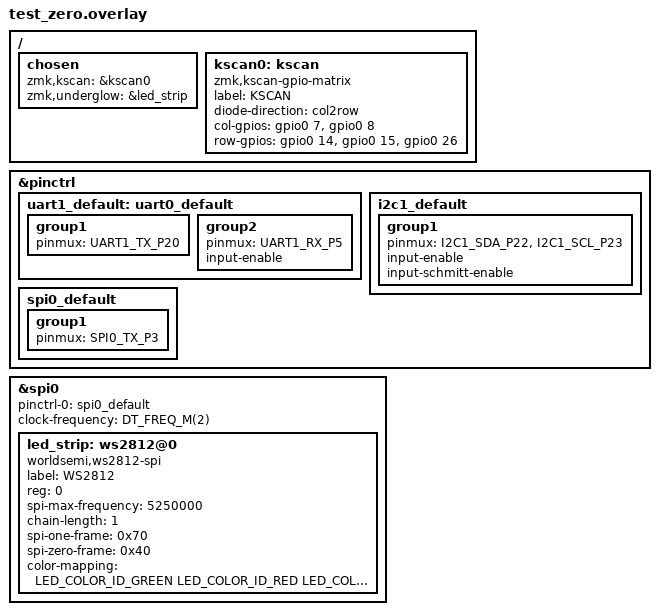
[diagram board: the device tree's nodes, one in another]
/*
 * Copyright (c) 2022 Gleb Sabirzyanov
 *
 * SPDX-License-Identifier: MIT
 */

#include <dt-bindings/zmk/matrix_transform.h>
#include <dt-bindings/led/led.h>


&pinctrl {
	uart1_default: uart0_default {
		group1 {
			pinmux = <UART1_TX_P20>;
		};
		group2 {
			pinmux = <UART1_RX_P5>;
			input-enable;
		};
	};

	i2c1_default: i2c1_default {
		group1 {
			pinmux = <I2C1_SDA_P22>, <I2C1_SCL_P23>;
			input-enable;
			input-schmitt-enable;
		};
	};


	spi0_default: spi0_default {
		group1 {
			pinmux = <SPI0_TX_P3>;
		};
	};
};

&spi0 {
	status = "okay";
	pinctrl-0 = <&spi0_default>;
	pinctrl-names = "default";
	clock-frequency = <DT_FREQ_M(2)>;
};

/ {
	chosen {
		zmk,kscan = &kscan0;
		zmk,underglow = &led_strip;
	};

	kscan0: kscan {
		compatible = "zmk,kscan-gpio-matrix";
		label = "KSCAN";

		diode-direction = "col2row";

    col-gpios
	    = <&gpio0 7 GPIO_ACTIVE_HIGH>
	    , <&gpio0 8 GPIO_ACTIVE_HIGH>
	    ;

    row-gpios
      = <&gpio0 14 (GPIO_ACTIVE_HIGH | GPIO_PULL_DOWN)>
      , <&gpio0 15 (GPIO_ACTIVE_HIGH | GPIO_PULL_DOWN)>
      , <&gpio0 26 (GPIO_ACTIVE_HIGH | GPIO_PULL_DOWN)>
      ;
	};

};

&spi0 {

  led_strip: ws2812@0 {
    compatible = "worldsemi,ws2812-spi";
    label = "WS2812";

    /* SPI */
    reg = <0>;
    spi-max-frequency = <5250000>;

    /* WS2812 */
    chain-length = <1>; /* number of LEDs */
    spi-one-frame = <0x70>; /* make sure to configure this properly for your SOC */
    spi-zero-frame = <0x40>; /* make sure to configure this properly for your SOC */
    color-mapping = <LED_COLOR_ID_GREEN
                          LED_COLOR_ID_RED
                          LED_COLOR_ID_BLUE>;
  };
};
